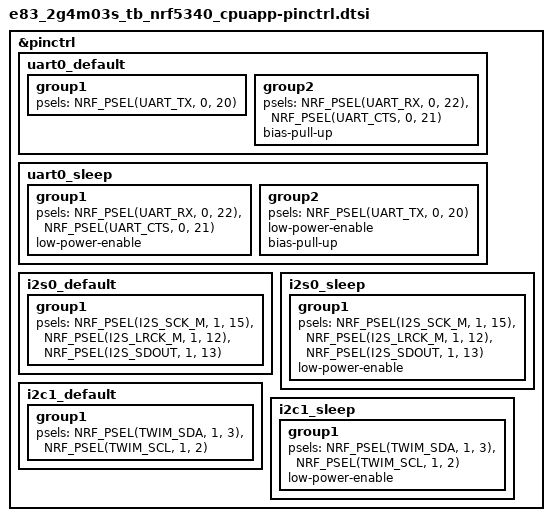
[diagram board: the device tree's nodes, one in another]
/*
 * Copyright (c) 2022 Nordic Semiconductor
 * SPDX-License-Identifier: Apache-2.0
 *
 * E83-2G4M03S Test Board (10414-PCB-V1.2) — application core pin control.
 *
 * UART0:  P0.20 TXD, P0.22 RXD, P0.21 CTS (CH340X USB-UART bridge)
 * I2S0:   P1.15 BCK, P1.13 DIN, P1.12 LRCK (CJMCU-1334 DAC)
 * I2C1:   P1.02 SCL, P1.03 SDA (available on P2 header for codec control)
 */

&pinctrl {
	uart0_default: uart0_default {
		group1 {
			psels = <NRF_PSEL(UART_TX, 0, 20)>;
		};

		group2 {
			psels = <NRF_PSEL(UART_RX, 0, 22)>,
				<NRF_PSEL(UART_CTS, 0, 21)>;
			bias-pull-up;
		};
	};

	uart0_sleep: uart0_sleep {
		group1 {
			psels = <NRF_PSEL(UART_RX, 0, 22)>,
				<NRF_PSEL(UART_CTS, 0, 21)>;
			low-power-enable;
		};

		group2 {
			psels = <NRF_PSEL(UART_TX, 0, 20)>;
			low-power-enable;
			bias-pull-up;
		};
	};

	i2s0_default: i2s0_default {
		group1 {
			psels = <NRF_PSEL(I2S_SCK_M, 1, 15)>,
				<NRF_PSEL(I2S_LRCK_M, 1, 12)>,
				<NRF_PSEL(I2S_SDOUT, 1, 13)>;
		};
	};

	i2s0_sleep: i2s0_sleep {
		group1 {
			psels = <NRF_PSEL(I2S_SCK_M, 1, 15)>,
				<NRF_PSEL(I2S_LRCK_M, 1, 12)>,
				<NRF_PSEL(I2S_SDOUT, 1, 13)>;
			low-power-enable;
		};
	};

	i2c1_default: i2c1_default {
		group1 {
			psels = <NRF_PSEL(TWIM_SDA, 1, 3)>,
				<NRF_PSEL(TWIM_SCL, 1, 2)>;
		};
	};

	i2c1_sleep: i2c1_sleep {
		group1 {
			psels = <NRF_PSEL(TWIM_SDA, 1, 3)>,
				<NRF_PSEL(TWIM_SCL, 1, 2)>;
			low-power-enable;
		};
	};
};
